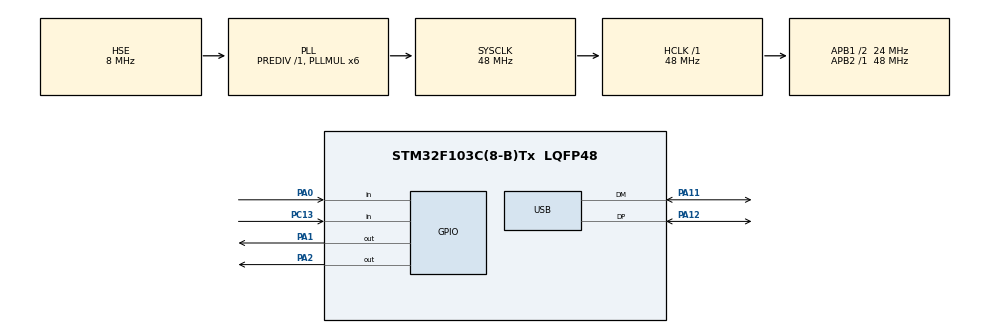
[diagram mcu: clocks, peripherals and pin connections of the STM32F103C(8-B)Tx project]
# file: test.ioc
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Mcu.Family=STM32F1
Mcu.Name=STM32F103C(8-B)Tx
Mcu.Package=LQFP48
NVIC.PriorityGroup=NVIC_PRIORITYGROUP_4
NVIC.USB_LP_CAN1_RX0_IRQn=true\:0\:0\:false\:false\:true\:false\:true\:true
PA0-WKUP.Signal=GPIO_Input
PA1.Signal=GPIO_Output
PA11.Mode=Device
PA11.Signal=USB_DM
PA12.Mode=Device
PA12.Signal=USB_DP
PA13.Mode=Serial_Wire
PA13.Signal=SYS_JTMS-SWDIO
PA14.Mode=Serial_Wire
PA14.Signal=SYS_JTCK-SWCLK
PA2.Signal=GPIO_Output
PC13-TAMPER-RTC.Signal=GPIO_Input
PD0-OSC_IN.Mode=HSE-External-Oscillator
PD0-OSC_IN.Signal=RCC_OSC_IN
PD1-OSC_OUT.Mode=HSE-External-Oscillator
PD1-OSC_OUT.Signal=RCC_OSC_OUT
ProjectManager.HeapSize=0x200
ProjectManager.StackSize=0x400
ProjectManager.TargetToolchain=MDK-ARM V5.32
RCC.AHBFreq_Value=48000000
RCC.APB1CLKDivider=RCC_HCLK_DIV2
RCC.APB1Freq_Value=24000000
RCC.APB1TimFreq_Value=48000000
RCC.APB2Freq_Value=48000000
RCC.APB2TimFreq_Value=48000000
RCC.HCLKFreq_Value=48000000
RCC.PLLMUL=RCC_PLL_MUL6
RCC.PLLSourceVirtual=RCC_PLLSOURCE_HSE
RCC.SYSCLKFreq_VALUE=48000000
RCC.SYSCLKSource=RCC_SYSCLKSOURCE_PLLCLK
RCC.USBFreq_Value=48000000
USB_DEVICE.CLASS_NAME_FS=CDC
USB_DEVICE.VirtualMode=Cdc
USB_DEVICE.VirtualModeFS=Cdc_FS
VP_USB_DEVICE_VS_USB_DEVICE_CDC_FS.Mode=CDC_FS
board=custom

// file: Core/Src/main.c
/* USER CODE BEGIN Header */
/**
  ******************************************************************************
  * @file           : main.c
  * @brief          : Main program body
  ******************************************************************************
  * @attention
  *
  * Copyright (c) 2023 STMicroelectronics.
  * All rights reserved.
  *
  * This software is licensed under terms that can be found in the LICENSE file
  * in the root directory of this software component.
  * If no LICENSE file comes with this software, it is provided AS-IS.
  *
  ******************************************************************************
  */
/* USER CODE END Header */
#include "main.h"
#include "bsp_rtc.h"
#include "usb_device.h"

void SystemClock_Config(void);
static void MX_GPIO_Init(void);

/* USER CODE BEGIN 0 */
uint8_t Key_Scan(GPIO_TypeDef* GPIOx,uint16_t GPIO_Pin);
void All(void);
void delay(void);
/* USER CODE END 0 */

int main(void)
{
  /* USER CODE BEGIN 1 */
	int KEY1=0,KEY2=0;
  /* USER CODE END 1 */

  /* MCU Configuration--------------------------------------------------------*/

  /* Reset of all peripherals, Initializes the Flash interface and the Systick. */
  HAL_Init();

  /* Configure the system clock */
  SystemClock_Config();

  /* Initialize all configured peripherals */
  MX_GPIO_Init();
  MX_USB_DEVICE_Init();
  /* USER CODE BEGIN 2 */
/*##-1- Configure the RTC peripheral #######################################*/
  /*配置RTC预分频器和RTC数据寄存器 */
  /*Asynch Prediv  = 由HAL自动计算 */
  Rtc_Handle.Instance = RTC;
  Rtc_Handle.Init.AsynchPrediv = RTC_AUTO_1_SECOND;

	 if (HAL_RTC_Init(&Rtc_Handle) != HAL_OK)
  {
    /* Initialization Error */
    //printf("\r\n RTC初始化失败\r\n");;
  }
  else
	{
    RTC_CalendarConfig();
		/* 检查是否电源复位 */
		if (__HAL_RCC_GET_FLAG(RCC_FLAG_PORRST) != RESET)
		{
		  //printf("\r\n 发生电源复位....\r\n");
		}
		/* 检查是否外部复位 */
		else if (__HAL_RCC_GET_FLAG(RCC_FLAG_PINRST) != RESET)
		{
		  //printf("\r\n 发生外部复位....\r\n");
		}
		HAL_GPIO_WritePin(GPIOA, GPIO_PIN_3, GPIO_PIN_RESET);
		/* Clear source Reset Flag */
    __HAL_RCC_CLEAR_RESET_FLAGS();
	}

  /* USER CODE END 2 */

  /* Infinite loop */
  while (1)
  {

    /* USER CODE BEGIN 3 */

			/* 显示时间和日期 */
		RTC_TimeAndDate_Show();

		if(Key_Scan(GPIOA,GPIO_PIN_0) == 1)
		{
			KEY1 = -1;
			HAL_GPIO_WritePin(GPIOA, GPIO_PIN_1, GPIO_PIN_RESET);
		}

				if(Key_Scan(GPIOC,GPIO_PIN_13) == 1)
		{
			KEY2 = -1;
			HAL_GPIO_WritePin(GPIOA, GPIO_PIN_2, GPIO_PIN_RESET);
		}

		if(KEY1 == -1 && KEY2 == -1)
			All();
  }
  /* USER CODE END 3 */
}

void SystemClock_Config(void)
{
  RCC_OscInitTypeDef RCC_OscInitStruct = {0};
  RCC_ClkInitTypeDef RCC_ClkInitStruct = {0};
  RCC_PeriphCLKInitTypeDef PeriphClkInit = {0};

  /** Initializes the RCC Oscillators according to the specified parameters
  * in the RCC_OscInitTypeDef structure.
  */
  RCC_OscInitStruct.OscillatorType = RCC_OSCILLATORTYPE_HSE;
  RCC_OscInitStruct.HSEState = RCC_HSE_ON;
  RCC_OscInitStruct.HSEPredivValue = RCC_HSE_PREDIV_DIV1;
  RCC_OscInitStruct.HSIState = RCC_HSI_ON;
  RCC_OscInitStruct.PLL.PLLState = RCC_PLL_ON;
  RCC_OscInitStruct.PLL.PLLSource = RCC_PLLSOURCE_HSE;
  RCC_OscInitStruct.PLL.PLLMUL = RCC_PLL_MUL6;
  if (HAL_RCC_OscConfig(&RCC_OscInitStruct) != HAL_OK)
  {
    Error_Handler();
  }

  /** Initializes the CPU, AHB and APB buses clocks
  */
  RCC_ClkInitStruct.ClockType = RCC_CLOCKTYPE_HCLK|RCC_CLOCKTYPE_SYSCLK
                              |RCC_CLOCKTYPE_PCLK1|RCC_CLOCKTYPE_PCLK2;
  RCC_ClkInitStruct.SYSCLKSource = RCC_SYSCLKSOURCE_PLLCLK;
  RCC_ClkInitStruct.AHBCLKDivider = RCC_SYSCLK_DIV1;
  RCC_ClkInitStruct.APB1CLKDivider = RCC_HCLK_DIV2;
  RCC_ClkInitStruct.APB2CLKDivider = RCC_HCLK_DIV1;

  if (HAL_RCC_ClockConfig(&RCC_ClkInitStruct, FLASH_LATENCY_1) != HAL_OK)
  {
    Error_Handler();
  }
  PeriphClkInit.PeriphClockSelection = RCC_PERIPHCLK_USB;
  PeriphClkInit.UsbClockSelection = RCC_USBCLKSOURCE_PLL;
  if (HAL_RCCEx_PeriphCLKConfig(&PeriphClkInit) != HAL_OK)
  {
    Error_Handler();
  }
}

static void MX_GPIO_Init(void)
{
  GPIO_InitTypeDef GPIO_InitStruct = {0};

  /* GPIO Ports Clock Enable */
  __HAL_RCC_GPIOC_CLK_ENABLE();
  __HAL_RCC_GPIOD_CLK_ENABLE();
  __HAL_RCC_GPIOA_CLK_ENABLE();

  /*Configure GPIO pin Output Level */
  HAL_GPIO_WritePin(GPIOA, GPIO_PIN_1|GPIO_PIN_2|GPIO_PIN_3, GPIO_PIN_SET);

  /*Configure GPIO pin : PC13 */
  GPIO_InitStruct.Pin = GPIO_PIN_13;
  GPIO_InitStruct.Mode = GPIO_MODE_INPUT;
  GPIO_InitStruct.Pull = GPIO_NOPULL;
  HAL_GPIO_Init(GPIOC, &GPIO_InitStruct);

  /*Configure GPIO pin : PA0 */
  GPIO_InitStruct.Pin = GPIO_PIN_0;
  GPIO_InitStruct.Mode = GPIO_MODE_INPUT;
  GPIO_InitStruct.Pull = GPIO_NOPULL;
  HAL_GPIO_Init(GPIOA, &GPIO_InitStruct);

  /*Configure GPIO pins : PA1 PA2 */
  GPIO_InitStruct.Pin = GPIO_PIN_1|GPIO_PIN_2|GPIO_PIN_3;
  GPIO_InitStruct.Mode = GPIO_MODE_OUTPUT_PP;
  GPIO_InitStruct.Pull = GPIO_NOPULL;
  GPIO_InitStruct.Speed = GPIO_SPEED_FREQ_LOW;
  HAL_GPIO_Init(GPIOA, &GPIO_InitStruct);

}

/* USER CODE BEGIN 4 */
uint8_t Key_Scan(GPIO_TypeDef* GPIOx,uint16_t GPIO_Pin)
{
	/*检测是否有按键按下 */
	if(HAL_GPIO_ReadPin(GPIOx,GPIO_Pin) == 1 )
	{
		/*等待按键释放 */
		while(HAL_GPIO_ReadPin(GPIOx,GPIO_Pin) == 1);
		return 	1;
	}
	else
		return 0;
}

void All(void)
{
	GPIO_InitTypeDef GPIO_InitStruct = {0};

	__HAL_RCC_GPIOC_CLK_ENABLE();
	__HAL_RCC_GPIOB_CLK_ENABLE();
  __HAL_RCC_GPIOD_CLK_ENABLE();
  __HAL_RCC_GPIOA_CLK_ENABLE();

//	__HAL_RCC_AFIO_CLK_ENABLE();
//

	HAL_GPIO_WritePin(GPIOA, GPIO_PIN_All, GPIO_PIN_RESET);
	HAL_GPIO_WritePin(GPIOB, GPIO_PIN_All, GPIO_PIN_RESET);
	HAL_GPIO_WritePin(GPIOC, GPIO_PIN_All, GPIO_PIN_RESET);
	HAL_GPIO_WritePin(GPIOD, GPIO_PIN_All, GPIO_PIN_RESET);

	GPIO_InitStruct.Pin = GPIO_PIN_All;
  GPIO_InitStruct.Mode = GPIO_MODE_OUTPUT_PP;
  GPIO_InitStruct.Pull = GPIO_NOPULL;
  GPIO_InitStruct.Speed = GPIO_SPEED_FREQ_LOW;
  HAL_GPIO_Init(GPIOA, &GPIO_InitStruct);
	HAL_GPIO_Init(GPIOB, &GPIO_InitStruct);
	HAL_GPIO_Init(GPIOC, &GPIO_InitStruct);
	HAL_GPIO_Init(GPIOD, &GPIO_InitStruct);
}

void delay()
{
	int a,b,c;
	for(a=0;a<100;a++)
	for(b=0;b<100;b++)
	for(c=0;c<100;c++);
}

/* USER CODE END 4 */

void Error_Handler(void)
{
  __disable_irq();
  while (1)
  {
  }
}
